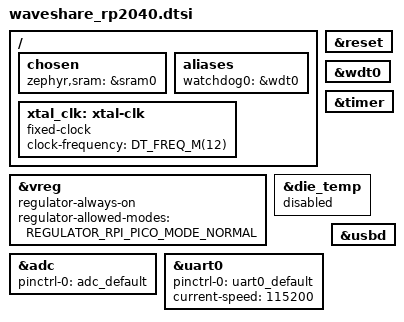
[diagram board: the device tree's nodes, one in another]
/*
 * Copyright (c) 2023 TiaC Systems
 * SPDX-License-Identifier: Apache-2.0
 */

#include <mem.h>
#include <freq.h>
#include <rpi_pico/rp2040.dtsi>
#include <zephyr/dt-bindings/regulator/rpi_pico.h>

#include "waveshare_rp2040-pinctrl.dtsi"

/ {
	chosen {
		zephyr,sram = &sram0;
	};

	aliases {
		watchdog0 = &wdt0;
	};

	xtal_clk: xtal-clk {
		compatible = "fixed-clock";
		clock-frequency = <DT_FREQ_M(12)>;
		#clock-cells = <0>;
	};

};

&vreg {
	regulator-always-on;
	regulator-allowed-modes = <REGULATOR_RPI_PICO_MODE_NORMAL>;
};

&reset {
	status = "okay";
};

&wdt0 {
	status = "okay";
};

&timer {
	status = "okay";
};

&die_temp {
	status = "disabled";
};

&adc {
	status = "okay";
	pinctrl-0 = <&adc_default>;
	pinctrl-names = "default";
};

&uart0 {
	status = "okay";
	pinctrl-0 = <&uart0_default>;
	pinctrl-names = "default";
	current-speed = <115200>;
};

zephyr_udc0: &usbd {
	status = "okay";
};
